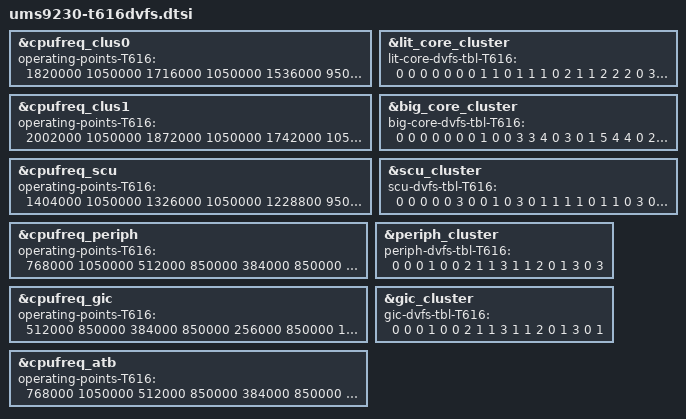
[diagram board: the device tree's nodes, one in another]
// SPDX-License-Identifier: (GPL-2.0+ OR MIT)
/*
 * Unisoc qogirl6 platform T616 SOC DVFS DTS file
 *
 * Copyright (C) 2021, Unisoc Communications Inc.
 */

#include "qogirl6.dtsi"
#include "ums9230.dtsi"

&cpufreq_clus0 {
	/* operating-points-T616-0-0
	 * T606/T616-soc_ver 0-binning 0-temp
	 */
	operating-points-T616 = <
		/* kHZ   uV */
		1820000 1050000
		1716000 1050000
		1536000 950000
		1482000 950000
		1228800 850000
		1144000 850000
		962000  850000
		768000  850000
		614400  750000
	>;
};

&cpufreq_clus1 {
	operating-points-T616 = <
		/* kHZ   uV */
		2002000 1050000
		1872000 1050000
		1742000 1050000
		1536000 950000
		1482000 850000
		1228800 800000
	>;
};

&cpufreq_scu {
	operating-points-T616 = <
		/* kHZ   uV */
		1404000 1050000
		1326000 1050000
		1228800 950000
		1118000 950000
		1014000 850000
		962000  850000
		768000  850000
		650000  850000
		546000  750000
	>;
};

&cpufreq_periph {
	operating-points-T616 = <
		/* kHZ   uV */
		768000  1050000
		512000  850000
		384000  850000
		256000  850000
		153600  750000
	>;
};

&cpufreq_gic {
	operating-points-T616 = <
		/* kHZ   uV */
		512000  850000
		384000  850000
		256000  850000
		192000  850000
		153600  750000
	>;
};

&cpufreq_atb {
	operating-points-T616 = <
		/* kHZ   uV */
		768000  1050000
		512000  850000
		384000  850000
		256000  750000
		153600  750000
	>;
};

&lit_core_cluster {
	/* lit-core-dvfs-tbl-T616-0-0
	 * T606/T616-soc_ver 0-binning 0-temp
	 * sel, div, vol, vote_scu, vote_peri, vote_gic, mpllx
	 */
	lit-core-dvfs-tbl-T616 = <
		0 0 0 0 0 0 0
		1 1 0 1 1 1 0
		2 1 1 2 2 2 0
		3 0 1 3 2 3 0
		3 0 1 4 3 4 1
		1 0 1 5 4 4 0
		3 0 2 6 4 4 2
		2 0 2 7 4 4 0
		3 0 3 8 4 5 4
		3 0 3 9 5 5 5
	>;
};

&big_core_cluster {
	/* sel, div, vol, vote_scu, vote_peri, vote_gic, mpllx */
	big-core-dvfs-tbl-T616 = <
		0 0 0 0 0 0 0
		1 0 0 3 3 4 0
		3 0 1 5 4 4 0
		2 0 2 6 4 4 0
		3 0 3 7 4 5 2
		3 0 3 8 4 5 4
		3 0 3 9 5 5 7
	>;
};

&scu_cluster {
	/* sel, div, vol, ace_div, mpllx */
	scu-dvfs-tbl-T616 = <
		0 0 0 0 0
		3 0 0 1 0
		3 0 1 1 1
		1 0 1 1 0
		3 0 1 1 2
		3 0 1 1 3
		3 0 2 1 4
		2 0 2 1 0
		3 0 3 1 6
		3 0 3 1 7
	>;
};

&periph_cluster{
	/* sel, div, vol */
	periph-dvfs-tbl-T616 = <
		0 0 0
		1 0 0
		2 1 1
		3 1 1
		2 0 1
		3 0 3
	>;
};

&gic_cluster{
	/* sel, div, vol */
	gic-dvfs-tbl-T616 = <
		0 0 0
		1 0 0
		2 1 1
		3 1 1
		2 0 1
		3 0 1
	>;
};
